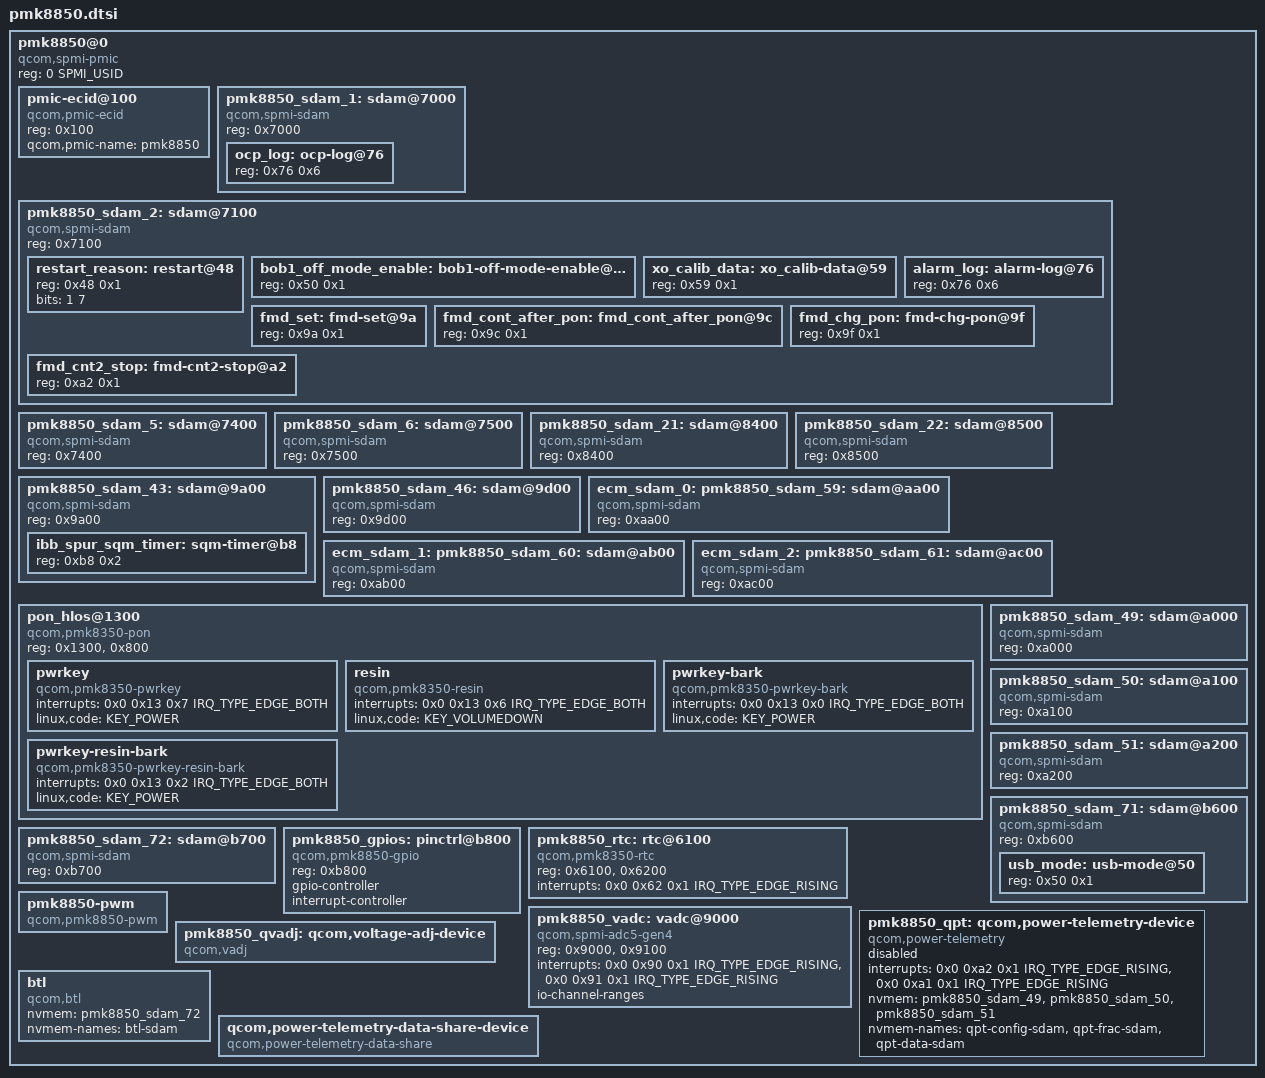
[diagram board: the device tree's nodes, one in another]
// SPDX-License-Identifier: BSD-3-Clause
/*
 * Copyright (c) 2024-2025 Qualcomm Innovation Center, Inc. All rights reserved.
 */

#include <dt-bindings/input/input.h>
#include <dt-bindings/interrupt-controller/irq.h>
#include <dt-bindings/spmi/spmi.h>

pmk8850@0 {
	compatible = "qcom,spmi-pmic";
	reg = <0 SPMI_USID>;
	#address-cells = <1>;
	#size-cells = <0>;

	pmic-ecid@100 {
		compatible = "qcom,pmic-ecid";
		reg = <0x100>;
		qcom,pmic-name = "pmk8850";
};

	pmk8850_sdam_1: sdam@7000 {
		compatible = "qcom,spmi-sdam";
		reg = <0x7000>;
		#address-cells = <1>;
		#size-cells = <1>;

		ocp_log: ocp-log@76 {
			reg = <0x76 0x6>;
		};
	};

	pmk8850_sdam_2: sdam@7100 {
		compatible = "qcom,spmi-sdam";
		reg = <0x7100>;
		#address-cells = <1>;
		#size-cells = <1>;

		restart_reason: restart@48 {
			reg = <0x48 0x1>;
			bits = <1 7>;
		};

		bob1_off_mode_enable: bob1-off-mode-enable@50 {
			reg = <0x50 0x1>;
		};

		xo_calib_data: xo_calib-data@59 {
			reg = <0x59 0x1>;
		};

		alarm_log: alarm-log@76 {
			reg = <0x76 0x6>;
		};

		fmd_set: fmd-set@9a {
			reg = <0x9a 0x1>;
		};

		fmd_cont_after_pon: fmd_cont_after_pon@9c {
			reg = <0x9c 0x1>;
		};

		fmd_chg_pon: fmd-chg-pon@9f {
			reg = <0x9f 0x1>;
		};

		fmd_cnt2_stop: fmd-cnt2-stop@a2 {
			reg = <0xa2 0x1>;
		};
	};

	pmk8850_sdam_5: sdam@7400 {
		compatible = "qcom,spmi-sdam";
		reg = <0x7400>;
	};

	pmk8850_sdam_6: sdam@7500 {
		compatible = "qcom,spmi-sdam";
		reg = <0x7500>;
	};

	pmk8850_sdam_21: sdam@8400 {
		compatible = "qcom,spmi-sdam";
		reg = <0x8400>;
	};

	pmk8850_sdam_22: sdam@8500 {
		compatible = "qcom,spmi-sdam";
		reg = <0x8500>;
	};

	pmk8850_sdam_43: sdam@9a00 {
		compatible = "qcom,spmi-sdam";
		reg = <0x9a00>;
		#address-cells = <1>;
		#size-cells = <1>;

		ibb_spur_sqm_timer: sqm-timer@b8 {
			reg = <0xb8 0x2>;
		};
	};

	pmk8850_sdam_46: sdam@9d00 {
		compatible = "qcom,spmi-sdam";
		reg = <0x9d00>;
	};

	ecm_sdam_0: pmk8850_sdam_59: sdam@aa00 {
		compatible = "qcom,spmi-sdam";
		reg = <0xaa00>;
	};

	ecm_sdam_1: pmk8850_sdam_60: sdam@ab00 {
		compatible = "qcom,spmi-sdam";
		reg = <0xab00>;
	};

	ecm_sdam_2: pmk8850_sdam_61: sdam@ac00 {
		compatible = "qcom,spmi-sdam";
		reg = <0xac00>;
	};

	pon_hlos@1300 {
		compatible = "qcom,pmk8350-pon";
		reg = <0x1300>, <0x800>;
		reg-names = "hlos", "pbs";

		pwrkey {
			compatible = "qcom,pmk8350-pwrkey";
			interrupts = <0x0 0x13 0x7 IRQ_TYPE_EDGE_BOTH>;
			linux,code = <KEY_POWER>;
		};

		resin {
			compatible = "qcom,pmk8350-resin";
			interrupts = <0x0 0x13 0x6 IRQ_TYPE_EDGE_BOTH>;
			linux,code = <KEY_VOLUMEDOWN>;
		};

		pwrkey-bark {
			compatible = "qcom,pmk8350-pwrkey-bark";
			interrupts = <0x0 0x13 0x0 IRQ_TYPE_EDGE_BOTH>;
			linux,code = <KEY_POWER>;
		};

		pwrkey-resin-bark {
			compatible = "qcom,pmk8350-pwrkey-resin-bark";
			interrupts = <0x0 0x13 0x2 IRQ_TYPE_EDGE_BOTH>;
			linux,code = <KEY_POWER>;
		};
	};

	pmk8850_sdam_49: sdam@a000 {
		compatible = "qcom,spmi-sdam";
		reg = <0xa000>;
	};

	pmk8850_sdam_50: sdam@a100 {
		compatible = "qcom,spmi-sdam";
		reg = <0xa100>;
	};

	pmk8850_sdam_51: sdam@a200 {
		compatible = "qcom,spmi-sdam";
		reg = <0xa200>;
	};

	pmk8850_sdam_71: sdam@b600 {
		compatible = "qcom,spmi-sdam";
		reg = <0xb600>;
		usb_mode: usb-mode@50 {
			reg = <0x50 0x1>;
		};
	};

	pmk8850_sdam_72: sdam@b700 {
		compatible = "qcom,spmi-sdam";
		reg = <0xb700>;
	};

	pmk8850_gpios: pinctrl@b800 {
		compatible = "qcom,pmk8850-gpio";
		reg = <0xb800>;
		gpio-controller;
		#gpio-cells = <2>;
		interrupt-controller;
		#interrupt-cells = <2>;
	};

	pmk8850_rtc: rtc@6100 {
		compatible = "qcom,pmk8350-rtc";
		reg = <0x6100>, <0x6200>;
		reg-names = "rtc", "alarm";
		interrupts = <0x0 0x62 0x1 IRQ_TYPE_EDGE_RISING>;
	};

	pmk8850-pwm {
		compatible = "qcom,pmk8850-pwm", "qcom,pmk8550-pwm";
		#address-cells = <1>;
		#size-cells = <0>;
		#pwm-cells = <2>;
	};

	pmk8850_vadc: vadc@9000 {
		compatible = "qcom,spmi-adc5-gen4";
		reg = <0x9000>, <0x9100>;
		#address-cells = <1>;
		#size-cells = <0>;
		interrupts = <0x0 0x90 0x1 IRQ_TYPE_EDGE_RISING>,
			     <0x0 0x91 0x1 IRQ_TYPE_EDGE_RISING>;
		interrupt-names = "adc-sdam0", "adc-sdam1";
		#thermal-sensor-cells = <1>;
		#io-channel-cells = <1>;
		io-channel-ranges;
	};

	pmk8850_qpt: qcom,power-telemetry-device {
		compatible = "qcom,power-telemetry";
		status = "disabled";
		interrupts = <0x0 0xa2 0x1 IRQ_TYPE_EDGE_RISING>,
				<0x0 0xa1 0x1 IRQ_TYPE_EDGE_RISING>;
		nvmem = <&pmk8850_sdam_49>,
				<&pmk8850_sdam_50>,
				<&pmk8850_sdam_51>;
		nvmem-names = "qpt-config-sdam",
				"qpt-frac-sdam",
				"qpt-data-sdam";
		#powerzone-cells = <1>;
	};

	pmk8850_qvadj: qcom,voltage-adj-device {
		compatible = "qcom,vadj";
	};

	btl {
		compatible = "qcom,btl";
		nvmem = <&pmk8850_sdam_72>;
		nvmem-names = "btl-sdam";
	};

	qcom,power-telemetry-data-share-device {
		compatible = "qcom,power-telemetry-data-share";
	};
};
